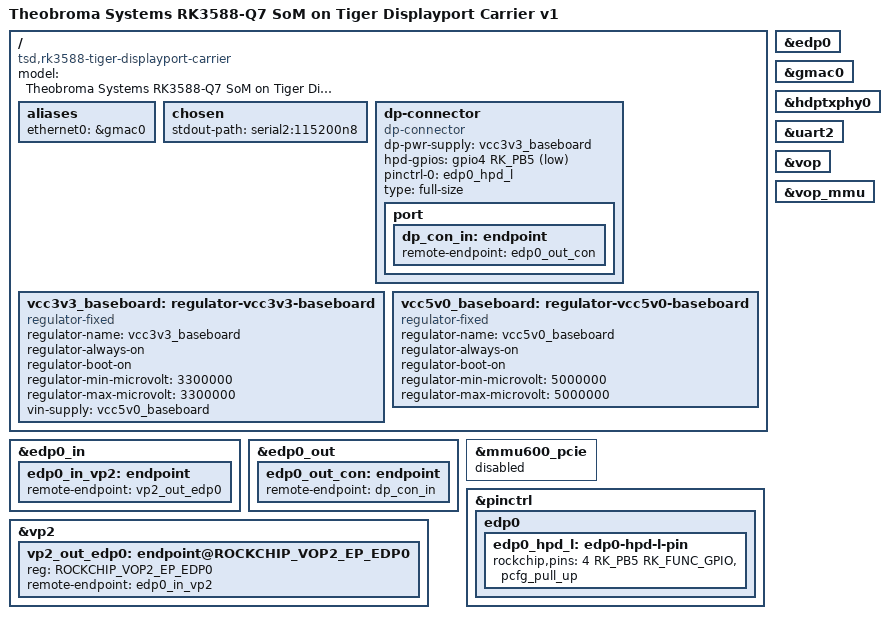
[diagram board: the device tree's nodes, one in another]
// SPDX-License-Identifier: (GPL-2.0+ OR MIT)
/*
 * Copyright (c) 2024 Cherry Embedded Solutions GmbH
 */

/dts-v1/;
#include <dt-bindings/soc/rockchip,vop2.h>
#include "rk3588-tiger.dtsi"

/ {
	model = "Theobroma Systems RK3588-Q7 SoM on Tiger Displayport Carrier v1";
	compatible = "tsd,rk3588-tiger-displayport-carrier", "tsd,rk3588-tiger", "rockchip,rk3588";

	aliases {
		ethernet0 = &gmac0;
	};

	chosen {
		stdout-path = "serial2:115200n8";
	};

	dp-connector {
		compatible = "dp-connector";
		dp-pwr-supply = <&vcc3v3_baseboard>;
		hpd-gpios = <&gpio4 RK_PB5 GPIO_ACTIVE_LOW>;
		pinctrl-0 = <&edp0_hpd_l>;
		pinctrl-names = "default";
		type = "full-size";

		port {
			dp_con_in: endpoint {
				remote-endpoint = <&edp0_out_con>;
			};
		};
	};

	vcc3v3_baseboard: regulator-vcc3v3-baseboard {
		compatible = "regulator-fixed";
		regulator-name = "vcc3v3_baseboard";
		regulator-always-on;
		regulator-boot-on;
		regulator-min-microvolt = <3300000>;
		regulator-max-microvolt = <3300000>;
		vin-supply = <&vcc5v0_baseboard>;
	};

	vcc5v0_baseboard: regulator-vcc5v0-baseboard {
		compatible = "regulator-fixed";
		regulator-name = "vcc5v0_baseboard";
		regulator-always-on;
		regulator-boot-on;
		regulator-min-microvolt = <5000000>;
		regulator-max-microvolt = <5000000>;
	};
};

&edp0 {
	status = "okay";
};

&edp0_in {
	edp0_in_vp2: endpoint {
		remote-endpoint = <&vp2_out_edp0>;
	};
};

&edp0_out {
	edp0_out_con: endpoint {
		remote-endpoint = <&dp_con_in>;
	};
};

&gmac0 {
	status = "okay";
};

&hdptxphy0 {
	status = "okay";
};

&mmu600_pcie {
	status = "disabled";
};

&pinctrl {
	edp0 {
		edp0_hpd_l: edp0-hpd-l-pin {
			rockchip,pins = <4 RK_PB5 RK_FUNC_GPIO &pcfg_pull_up>;
		};
	};
};

&uart2 {
	status = "okay";
};

&vop {
	status = "okay";
};

&vop_mmu {
	status = "okay";
};

&vp2 {
	vp2_out_edp0: endpoint@ROCKCHIP_VOP2_EP_EDP0 {
		reg = <ROCKCHIP_VOP2_EP_EDP0>;
		remote-endpoint = <&edp0_in_vp2>;
	};
};
